# haltium_cellcore register map
Vendor: Nordic Semiconductor; Series: nRFHaltium; File version: 1
CPU: CM33 r0p4, little endian, MPU, FPU, 3 interrupt priority bits, 480 interrupts
Registers are 32-bit, read-write, reset 0x0 unless marked. A register's access mark holds for its fields unless they carry their own. Offsets are from the block's base; [hi:lo] are bit positions; lines under a group give offsets from that group; {n}, {i} and the like mark numbered series; 'fields as' and 'values as' point back to an identical list.

## CPUC_S — CM33 SubSystem
Base 0xE0080000
0x100 EVENTS_FPUIOC — An invalid operation exception has occurred in the FPU.
  [0] EVENTS_FPUIOC
    0=NotGenerated (Event not generated); 1=Generated (Event generated)
0x104 EVENTS_FPUDZC — A floating-point divide-by-zero exception has occurred in the FPU.
  [0] EVENTS_FPUDZC
    values as EVENTS_FPUIOC.EVENTS_FPUIOC
0x108 EVENTS_FPUOFC — A floating-point overflow exception has occurred in the FPU.
  [0] EVENTS_FPUOFC
    values as EVENTS_FPUIOC.EVENTS_FPUIOC
0x10C EVENTS_FPUUFC — A floating-point underflow exception has occurred in the FPU.
  [0] EVENTS_FPUUFC
    values as EVENTS_FPUIOC.EVENTS_FPUIOC
0x110 EVENTS_FPUIXC — A floating-point inexact exception has occurred in the FPU.
  [0] EVENTS_FPUIXC
    values as EVENTS_FPUIOC.EVENTS_FPUIOC
0x114 EVENTS_FPUIDC — A floating-point input denormal exception has occurred in the FPU.
  [0] EVENTS_FPUIDC
    values as EVENTS_FPUIOC.EVENTS_FPUIOC
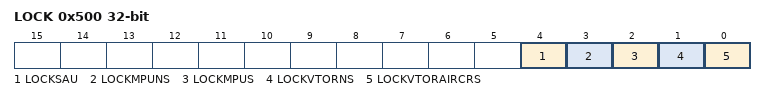
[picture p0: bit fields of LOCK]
0x500 LOCK — Register to lock the certain parts of the CPU from being modified.
  [4] LOCKSAU — Locks the Security Attribution Unit (SAU)
    0=NotLocked (SAU registers can be changed.); 1=Locked (Prevents changes to SAU registers.)
  [3] LOCKMPUNS — Locks the Memory Protection Unit (MPU) for non secure mode.
    0=NotLocked (MPU registers can be changed.); 1=Locked (Prevents changes to MPU registers.)
  [2] LOCKMPUS — Locks the Memory Protection Unit (MPU) for secure mode.
    values as LOCKMPUNS
  [1] LOCKVTORNS — Locks the Vector table Offset Register (VTOR) for non-secure mode.
    0=NotLocked (VTOR can be changed.); 1=Locked (Prevents changes to VTOR.)
  [0] LOCKVTORAIRCRS — Locks both the Vector table Offset Register (VTOR) and Application Interrupt and Reset Control Register (AIRCR) for secure mode.
    0=NotLocked (Both VTOR and AIRCR can be changed.); 1=Locked (Prevents changes to both VTOR and AIRCR.)
0x504 CPUID ro — The identifier for the CPU in this subsystem.
  [31:0] CPUID — The CPU identifier.

## LRCCONF0_S — LRCCONF 0
Base 0x54002000
Same registers: LRCCONF1_S 0x54011000, LRCCONF3_S 0x54031000
{0x0+4i} TASKS_REQCLKSRC[{i}] (i=0..7) wo — Description collection: Request the clock source for clock [n]
  [0] TASKS_REQCLKSRC — Request the clock source for clock [n]
    1=Trigger task
{0x20+4i} TASKS_STOPREQCLKSRC[{i}] (i=0..7) wo — Description collection: Stop requesting the clock source for clock [n]
  [0] TASKS_STOPREQCLKSRC — Stop requesting the clock source for clock [n]
    1=Trigger task
0x40 TASKS_CONSTLAT group — Peripheral tasks.
  0x00 ENABLE wo — Enable constant latency mode
    [0] ENABLE
      1=Trigger task
  0x04 DISABLE wo — Disable constant latency mode
    [0] DISABLE
      1=Trigger task
0x48 TASKS_SYSTEMOFF group — Peripheral tasks.
  0x00 NOTREADY wo — Not ready to go to System OFF
    [0] NOTREADY
      1=Trigger task
  0x04 READY wo — Ready to go to System OFF
    [0] READY
      1=Trigger task
{0x100+4i} EVENTS_CLKSRCSTARTED[{i}] (i=0..7) — Description collection: Clock source is started for clock [n]
  [0] EVENTS_CLKSRCSTARTED — Clock source is started for clock [n]
    0=NotGenerated (Event not generated); 1=Generated (Event generated)
{0x400+8i} CLKSTAT[{i}] (i=0..7) group — Unspecified
  0x00 RUN — Description cluster: Status indicating that TASKS_REQCLKSRC task has been triggered for clock [n].
    [0] STATUS ro — Clock start task triggered or not
      0=NotTriggered (Task not triggered); 1=Triggered (Task triggered)
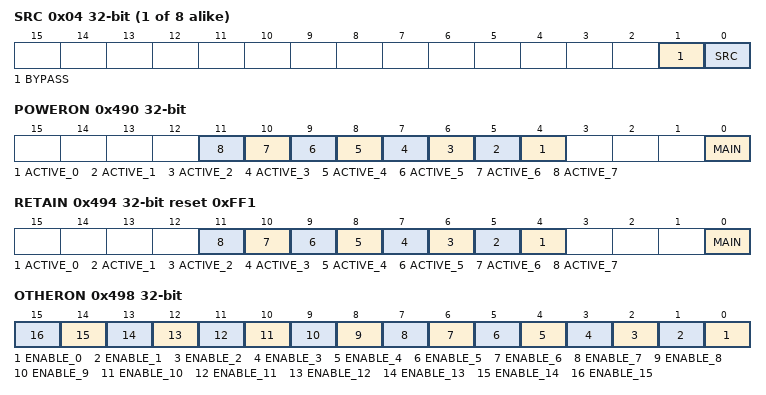
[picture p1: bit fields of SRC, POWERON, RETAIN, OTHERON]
  0x04 SRC — Description cluster: Status indicating clock source for clock [n]
    [1] BYPASS ro — Clock source bypass status
      0=Disable (Clock source bypass is disabled.); 1=Enable (Clock source bypass is enabled.)
    [0] SRC ro — Clock source status
      0=OpenLoop; 1=ClosedLoop
{0x440+8i} CLKCTRL[{i}] (i=0..7) group — Unspecified
  0x00 ALWAYSRUN — Description cluster: Force the clock [n] and tree running always
    [0] FORCE — Force the clock always running
      0=Automatic clock control enabled; 1=AlwaysRun (Clock always running)
  0x04 SRC — Description cluster: Select the clock source for clock [n]
    [1] BYPASS — Clock source bypass
      0=Disable the clock source bypass; 1=Enable the clock source bypass
    [0] SRC — Clock source
      0=OpenLoop; 1=ClosedLoop
0x480 CONSTLATSTAT ro — Status of constant latency
  [0] STATUS
    0=Disable (Constant latency disabled.); 1=Enable (Constant latency enabled.)
0x490 POWERON — Force power domain ON
  [all] fields
    0=Automatic power control enabled; 1=AlwaysOn (Keep the power domain ON even though there is no request)
  [n+4] ACTIVE_{n} (n=0..7) — Force the active power domain[{n}] ON
  [0] MAIN — Force the main power domain ON
0x494 RETAIN reset 0xFF1 — Retain power domain
  [all] fields
    0=Disable (Retain disabled); 1=Enable (Retain enabled)
  [n+4] ACTIVE_{n} (n=0..7) — Retain the active power domain[{n}]
  [0] MAIN ro — Retain the main power domain
0x498 OTHERON — Request other domain ON
  [all] fields
    0=Automatic power control enabled; 1=AlwaysOn (Request to keep the other power domain ON even though there is no request)
  [n] ENABLE_{n} (n=0..15) — Request power domain[{n}] ON
{0x500+4i} AX2XWAITSTATES[{i}] (i=0..15) reset 0x7 — Description collection: AX2X bridge waitstates for the domain [n], where n is the Domain ID.
  [2:0] WAITSTATES — Number of waitstates
